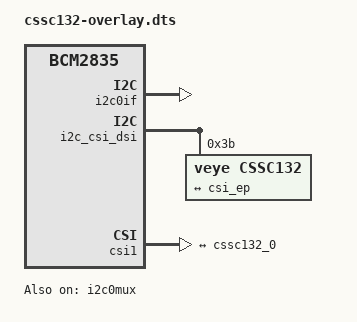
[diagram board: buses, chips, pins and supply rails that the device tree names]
// SPDX-License-Identifier: GPL-2.0-only
// Definitions for CS-MIPI-SC132 camera module on VC I2C bus
/dts-v1/;
/plugin/;

#include <dt-bindings/gpio/gpio.h>

/{
	compatible = "brcm,bcm2835";

	fragment@0 {
		target = <&i2c0if>;
		__overlay__ {
			status = "okay";
		};
	};

	clk_frag: fragment@1 {
		target = <&cam1_clk>;
		__overlay__ {
			status = "okay";
			clock-frequency = <24000000>;
		};
	};

	fragment@2 {
		target = <&i2c0mux>;
		__overlay__ {
			status = "okay";
		};
	};
	i2c_frag: fragment@100 {
		target = <&i2c_csi_dsi>;
		__overlay__ {
			#address-cells = <1>;
			#size-cells = <0>;
			status = "okay";

			cssc132: cssc132@3b {
				compatible = "veye,cssc132";
				reg = <0x3b>;
				status = "okay";


				rotation = <0>;

				port {
					cssc132_0: endpoint {
						remote-endpoint = <&csi_ep>;
						clock-lanes = <0>;
						data-lanes = <1 2>;
						clock-noncontinuous;
						link-frequencies =
							/bits/ 64 <297000000>;
					};
				};
			};
		};
	};

	csi_frag: fragment@101 {
		target = <&csi1>;
		csi: __overlay__ {
			status = "okay";

			port {
				csi_ep: endpoint {
					remote-endpoint = <&cssc132_0>;
					clock-lanes = <0>;
					data-lanes = <1 2>;
					clock-noncontinuous;
				};
			};
		};
	};



	__overrides__ {
		rotation = <&cssc132>,"rotation:0";
		cam0 = <&i2c_frag>, "target:0=",<&i2c_vc>,
		       <&csi_frag>, "target:0=",<&csi0>,
		       <&clk_frag>, "target:0=",<&cam0_clk>;

	};


};
